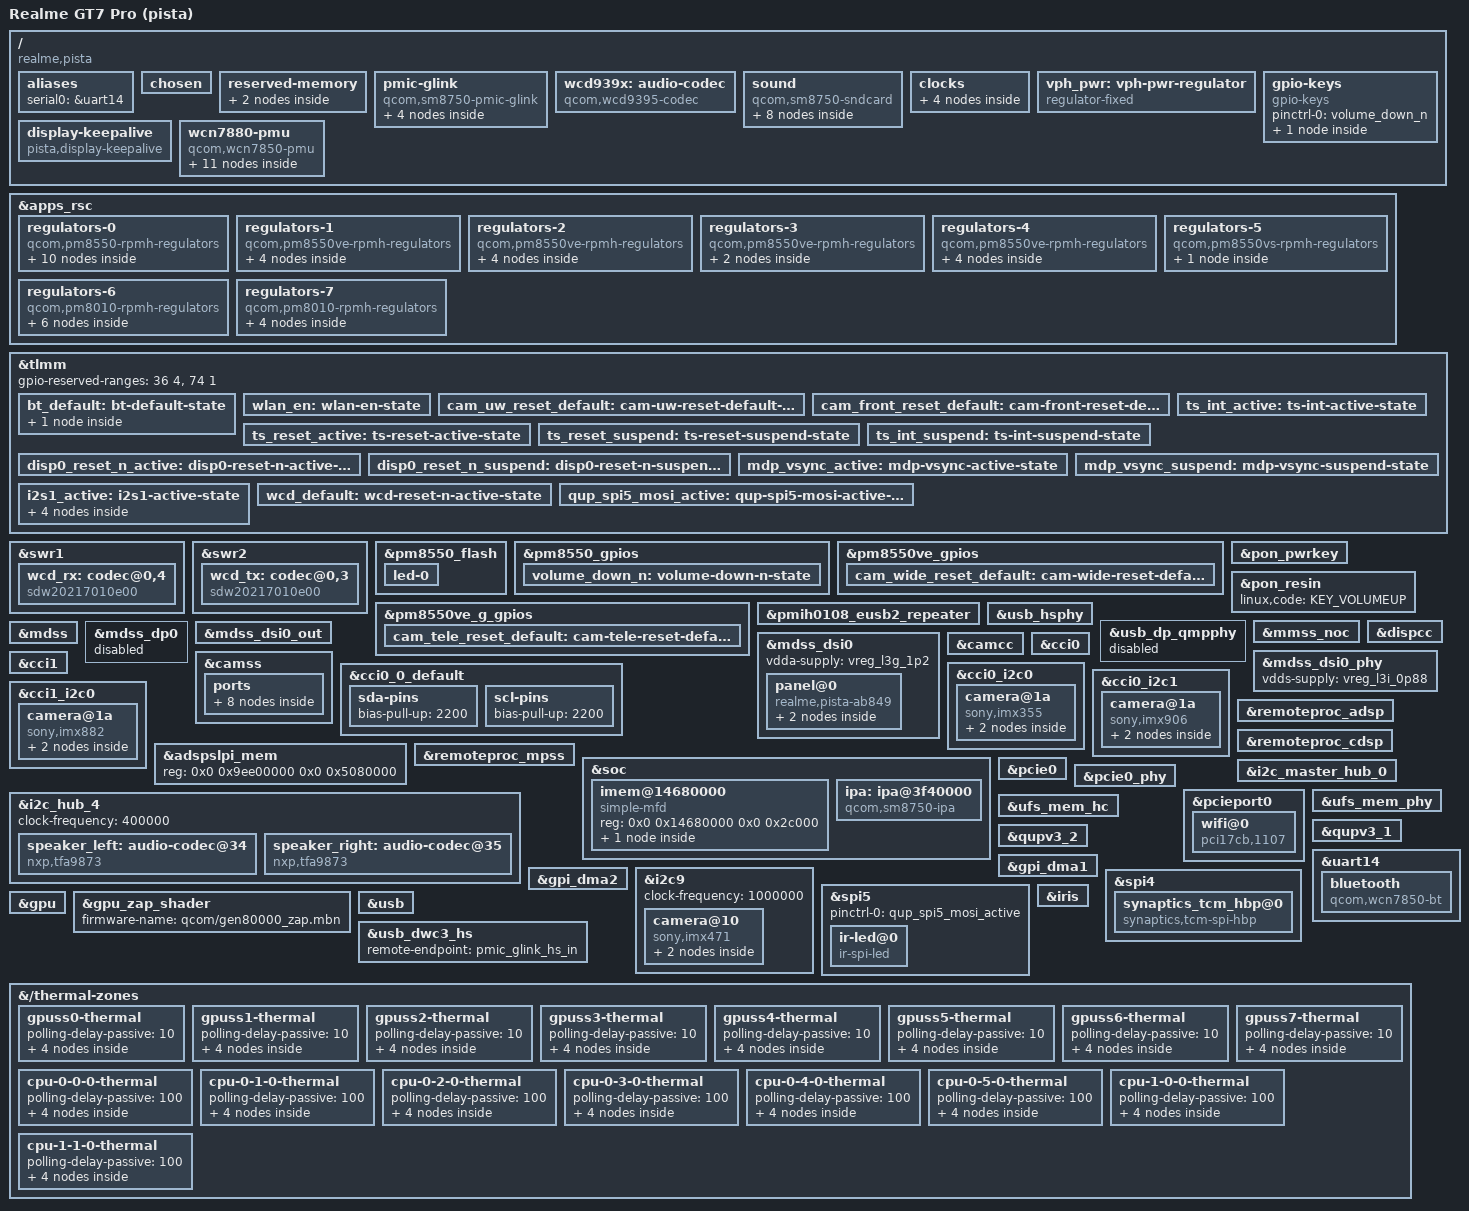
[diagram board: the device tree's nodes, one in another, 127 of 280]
// SPDX-License-Identifier: BSD-3-Clause
/*
 * Realme GT7 Pro (pista / RMX5010) mainline DT:
 * UEFI SimpleDRM + USB 2.0 Gadget + PCIe0 WCN7860 (peach) Wi-Fi 7 + UFS
 */

/dts-v1/;

#include <dt-bindings/firmware/qcom,scm.h>
#include <dt-bindings/gpio/gpio.h>
#include <dt-bindings/input/linux-event-codes.h>
#include <dt-bindings/leds/common.h>
#include <dt-bindings/regulator/qcom,rpmh-regulator.h>
#include <dt-bindings/thermal/thermal.h>
#include "sm8750.dtsi"
#include "pm8550.dtsi"
#define PMK8550VE_SID 8
#include "pm8550ve.dtsi"
#include "pmih0108.dtsi"
#include "pmk8550.dtsi"
#include "sm8750-pmics.dtsi"

/ {
	model = "Realme GT7 Pro (pista)";
	compatible = "realme,pista", "qcom,sm8750";
	chassis-type = "handset";

	aliases {
		serial0 = &uart14;
	};

	chosen {
		/* cmdline and EFI GOP framebuffer come from UEFI */
	};

	reserved-memory {
		rmtfs_mem: rmtfs@d7c00000 {
			compatible = "qcom,rmtfs-mem";
			reg = <0x0 0xd7c00000 0x0 0x400000>;
			no-map;

			qcom,client-id = <1>;
			qcom,vmid = <QCOM_SCM_VMID_MSS_MSA>;
		};
	};

	pmic-glink {
		compatible = "qcom,sm8750-pmic-glink",
			     "qcom,sm8550-pmic-glink",
			     "qcom,pmic-glink";
		#address-cells = <1>;
		#size-cells = <0>;

		connector@0 {
			compatible = "usb-c-connector";
			reg = <0>;

			power-role = "dual";
			data-role = "dual";

			ports {
				#address-cells = <1>;
				#size-cells = <0>;

				port@0 {
					reg = <0>;

					pmic_glink_hs_in: endpoint {
						remote-endpoint = <&usb_dwc3_hs>;
					};
				};
			};
		};
	};

	wcd939x: audio-codec {
		compatible = "qcom,wcd9395-codec", "qcom,wcd9390-codec";

		pinctrl-0 = <&wcd_default>;
		pinctrl-names = "default";

		qcom,micbias1-microvolt = <2700000>;
		qcom,micbias2-microvolt = <2700000>;
		qcom,micbias3-microvolt = <2700000>;
		qcom,micbias4-microvolt = <2700000>;
		qcom,mbhc-buttons-vthreshold-microvolt = <75000 150000 237000 500000 500000 500000 500000 500000>;
		qcom,mbhc-headset-vthreshold-microvolt = <1700000>;
		qcom,mbhc-headphone-vthreshold-microvolt = <50000>;
		qcom,rx-device = <&wcd_rx>;
		qcom,tx-device = <&wcd_tx>;

		reset-gpios = <&tlmm 101 GPIO_ACTIVE_LOW>;

		vdd-buck-supply = <&vreg_l15b_1p8>;
		vdd-rxtx-supply = <&vreg_l15b_1p8>;
		vdd-io-supply = <&vreg_l15b_1p8>;
		vdd-mic-bias-supply = <&vreg_bob1>;
		vdd-px-supply = <&vreg_l2i_1p2>;

		#sound-dai-cells = <1>;
	};

	sound {
		compatible = "qcom,sm8750-sndcard";
		model = "Realme-pista";

		pinctrl-0 = <&i2s1_active>;
		pinctrl-names = "default";

		audio-routing = "AMIC1", "MIC BIAS1",
				"AMIC2", "MIC BIAS2",
				"AMIC3", "MIC BIAS4",
				"AMIC4", "MIC BIAS3",
				"AMIC5", "MIC BIAS3",
				"TX SWR_INPUT0", "ADC1_OUTPUT",
				"TX SWR_INPUT1", "ADC2_OUTPUT",
				"TX SWR_INPUT2", "ADC3_OUTPUT",
				"TX SWR_INPUT3", "ADC4_OUTPUT";

		speaker-dai-link {
			link-name = "Speaker Playback";

			cpu {
				sound-dai = <&q6apmbedai SECONDARY_MI2S_RX>;
			};

			codec {
				sound-dai = <&speaker_left>, <&speaker_right>;
			};

			platform {
				sound-dai = <&q6apm>;
			};
		};

		wcd-capture-dai-link {
			link-name = "WCD Capture";

			codec {
				sound-dai = <&wcd939x 1>, <&swr2 0>, <&lpass_txmacro 0>;
			};

			cpu {
				sound-dai = <&q6apmbedai TX_CODEC_DMA_TX_3>;
			};

			platform {
				sound-dai = <&q6apm>;
			};
		};
	};

	reserved-memory {
		display_reserved: framebuffer@fc800000 {
			reg = <0x0 0xfc800000 0x0 0x2b00000>;
			no-map;
		};
	};

	clocks {
		xo_board: xo-board {
			compatible = "fixed-clock";
			clock-frequency = <76800000>;
			#clock-cells = <0>;
		};

		sleep_clk: sleep-clk {
			compatible = "fixed-clock";
			clock-frequency = <32000>;
			#clock-cells = <0>;
		};

		bi_tcxo_div2: bi-tcxo-div2-clk {
			compatible = "fixed-factor-clock";
			#clock-cells = <0>;
			clocks = <&rpmhcc RPMH_CXO_CLK>;
			clock-mult = <1>;
			clock-div = <2>;
		};

		bi_tcxo_ao_div2: bi-tcxo-ao-div2-clk {
			compatible = "fixed-factor-clock";
			#clock-cells = <0>;
			clocks = <&rpmhcc RPMH_CXO_CLK_A>;
			clock-mult = <1>;
			clock-div = <2>;
		};
	};

	vph_pwr: vph-pwr-regulator {
		compatible = "regulator-fixed";
		regulator-name = "vph_pwr";
		regulator-min-microvolt = <3700000>;
		regulator-max-microvolt = <3700000>;
		regulator-always-on;
		regulator-boot-on;
	};

	gpio-keys {
		compatible = "gpio-keys";

		pinctrl-0 = <&volume_down_n>;
		pinctrl-names = "default";

		key-volume-down {
			label = "Volume Down";
			linux,code = <KEY_VOLUMEDOWN>;
			gpios = <&pm8550_gpios 6 GPIO_ACTIVE_LOW>;
			debounce-interval = <15>;
			linux,can-disable;
			wakeup-source;
		};
	};

	/*
	 * Keep fw_devlink sync_state() pending on rpmhpd (MMCX), interconnects,
	 * and clocks so UEFI's active MDSS/OLED scanout is never powered down
	 * while running on simpledrm.
	 */
	display-keepalive {
		compatible = "pista,display-keepalive";
		power-domains = <&rpmhpd RPMHPD_MMCX>;
		interconnects = <&gem_noc MASTER_APPSS_PROC QCOM_ICC_TAG_ALWAYS
				 &mc_virt SLAVE_EBI1 QCOM_ICC_TAG_ALWAYS>,
				<&gem_noc MASTER_APPSS_PROC QCOM_ICC_TAG_ACTIVE_ONLY
				 &config_noc SLAVE_DISPLAY_CFG QCOM_ICC_TAG_ACTIVE_ONLY>;
		clocks = <&gcc GCC_DISP_HF_AXI_CLK>,
			 <&rpmhcc RPMH_CXO_CLK>;
		status = "okay";
	};

	/* Qualcomm FastConnect 7900 / WCN7860 (peach, PCI 17cb:110e) PMU */
	wcn7880-pmu {
		compatible = "qcom,wcn7850-pmu";

		pinctrl-names = "default";
		pinctrl-0 = <&wlan_en>, <&bt_default>;

		wlan-enable-gpios = <&tlmm 16 GPIO_ACTIVE_HIGH>;
		bt-enable-gpios = <&pm8550ve_f_gpios 3 GPIO_ACTIVE_HIGH>;

		vdd-supply = <&vreg_s5f_0p85>;
		vddio-supply = <&vreg_l3f_1p8>;
		vddio1p2-supply = <&vreg_l2f_1p2>;
		vddaon-supply = <&vreg_s4d_0p85>;
		vdddig-supply = <&vreg_s1d_0p97>;
		vddrfa1p2-supply = <&vreg_s7i_1p2>;
		vddrfa1p8-supply = <&vreg_s3g_1p8>;

		clocks = <&rpmhcc RPMH_RF_CLK1>;

		status = "okay";

		regulators {
			vreg_pmu_rfa_cmn: ldo0 {
				regulator-name = "vreg_pmu_rfa_cmn";
			};

			vreg_pmu_aon_0p59: ldo1 {
				regulator-name = "vreg_pmu_aon_0p59";
			};

			vreg_pmu_wlcx_0p8: ldo2 {
				regulator-name = "vreg_pmu_wlcx_0p8";
			};

			vreg_pmu_wlmx_0p85: ldo3 {
				regulator-name = "vreg_pmu_wlmx_0p85";
			};

			vreg_pmu_btcmx_0p85: ldo4 {
				regulator-name = "vreg_pmu_btcmx_0p85";
			};

			vreg_pmu_rfa_0p8: ldo5 {
				regulator-name = "vreg_pmu_rfa_0p8";
			};

			vreg_pmu_rfa_1p2: ldo6 {
				regulator-name = "vreg_pmu_rfa_1p2";
			};

			vreg_pmu_rfa_1p8: ldo7 {
				regulator-name = "vreg_pmu_rfa_1p8";
			};

			vreg_pmu_pcie_0p9: ldo8 {
				regulator-name = "vreg_pmu_pcie_0p9";
			};

			vreg_pmu_pcie_1p8: ldo9 {
				regulator-name = "vreg_pmu_pcie_1p8";
			};
		};
	};
};

&apps_rsc {
	regulators-0 {
		compatible = "qcom,pm8550-rpmh-regulators";

		vdd-bob1-supply = <&vph_pwr>;
		vdd-bob2-supply = <&vph_pwr>;
		vdd-l1-l4-l10-supply = <&vreg_s3g_1p8>;
		vdd-l2-l13-l14-supply = <&vreg_bob1>;
		vdd-l5-l16-supply = <&vreg_bob1>;
		vdd-l8-l9-supply = <&vreg_bob1>;
		vdd-l11-supply = <&vreg_s7i_1p2>;
		vdd-l12-supply = <&vreg_s3g_1p8>;
		vdd-l15-supply = <&vreg_s3g_1p8>;
		vdd-l17-supply = <&vreg_bob2>;

		qcom,pmic-id = "b";

		vreg_bob1: bob1 {
			regulator-name = "vreg_bob1";
			regulator-min-microvolt = <3008000>;
			regulator-max-microvolt = <4000000>;
			regulator-initial-mode = <RPMH_REGULATOR_MODE_HPM>;
		};

		vreg_bob2: bob2 {
			regulator-name = "vreg_bob2";
			regulator-min-microvolt = <2704000>;
			regulator-max-microvolt = <3008000>;
			regulator-initial-mode = <RPMH_REGULATOR_MODE_HPM>;
		};

		vreg_l4b_1p8: ldo4 {
			regulator-name = "vreg_l4b_1p8";
			regulator-min-microvolt = <1800000>;
			regulator-max-microvolt = <1800000>;
			regulator-initial-mode = <RPMH_REGULATOR_MODE_HPM>;
			regulator-allow-set-load;
			regulator-allowed-modes = <RPMH_REGULATOR_MODE_LPM
						   RPMH_REGULATOR_MODE_HPM>;
		};

		vreg_l5b_3p1: ldo5 {
			regulator-name = "vreg_l5b_3p1";
			regulator-min-microvolt = <3100000>;
			regulator-max-microvolt = <3148000>;
			regulator-initial-mode = <RPMH_REGULATOR_MODE_HPM>;
			regulator-allow-set-load;
			regulator-allowed-modes = <RPMH_REGULATOR_MODE_LPM
						   RPMH_REGULATOR_MODE_HPM>;
		};

		vreg_l9b_2p5: ldo9 {
			regulator-name = "vreg_l9b_2p5";
			regulator-min-microvolt = <2504000>;
			regulator-max-microvolt = <2504000>;
			regulator-initial-mode = <RPMH_REGULATOR_MODE_HPM>;
			regulator-allow-set-load;
			regulator-allowed-modes = <RPMH_REGULATOR_MODE_LPM
						   RPMH_REGULATOR_MODE_HPM>;
		};

		vreg_l11b_1p0: ldo11 {
			regulator-name = "vreg_l11b_1p0";
			regulator-min-microvolt = <1000000>;
			regulator-max-microvolt = <1100000>;
			regulator-initial-mode = <RPMH_REGULATOR_MODE_HPM>;
			regulator-allow-set-load;
			regulator-allowed-modes = <RPMH_REGULATOR_MODE_LPM
						   RPMH_REGULATOR_MODE_HPM>;
		};

		vreg_l12b_1p8: ldo12 {
			regulator-name = "vreg_l12b_1p8";
			regulator-min-microvolt = <1800000>;
			regulator-max-microvolt = <1800000>;
			regulator-initial-mode = <RPMH_REGULATOR_MODE_HPM>;
			regulator-allow-set-load;
			regulator-allowed-modes = <RPMH_REGULATOR_MODE_LPM
						   RPMH_REGULATOR_MODE_HPM>;
		};

		vreg_l13b_3p0: ldo13 {
			regulator-name = "vreg_l13b_3p0";
			regulator-min-microvolt = <3000000>;
			regulator-max-microvolt = <3000000>;
			regulator-initial-mode = <RPMH_REGULATOR_MODE_HPM>;
			regulator-allow-set-load;
			regulator-allowed-modes = <RPMH_REGULATOR_MODE_LPM
						   RPMH_REGULATOR_MODE_HPM>;
		};

		vreg_l15b_1p8: ldo15 {
			regulator-name = "vreg_l15b_1p8";
			regulator-min-microvolt = <1800000>;
			regulator-max-microvolt = <1800000>;
			regulator-initial-mode = <RPMH_REGULATOR_MODE_HPM>;
			regulator-allow-set-load;
			regulator-allowed-modes = <RPMH_REGULATOR_MODE_LPM
						   RPMH_REGULATOR_MODE_HPM>;
		};

		vreg_l17b_2p5: ldo17 {
			regulator-name = "vreg_l17b_2p5";
			regulator-min-microvolt = <2504000>;
			regulator-max-microvolt = <2504000>;
			regulator-initial-mode = <RPMH_REGULATOR_MODE_HPM>;
			regulator-allow-set-load;
			regulator-allowed-modes = <RPMH_REGULATOR_MODE_LPM
						   RPMH_REGULATOR_MODE_HPM>;
		};
	};

	regulators-1 {
		compatible = "qcom,pm8550ve-rpmh-regulators";

		vdd-l1-supply = <&vreg_s7i_1p2>;
		vdd-l2-supply = <&vreg_s1d_0p97>;
		vdd-s1-supply = <&vph_pwr>;
		vdd-s4-supply = <&vph_pwr>;

		qcom,pmic-id = "d";

		vreg_s1d_0p97: smps1 {
			regulator-name = "vreg_s1d_0p97";
			regulator-min-microvolt = <976000>;
			regulator-max-microvolt = <1100000>;
			regulator-initial-mode = <RPMH_REGULATOR_MODE_HPM>;
		};

		vreg_s4d_0p85: smps4 {
			regulator-name = "vreg_s4d_0p85";
			regulator-min-microvolt = <876000>;
			regulator-max-microvolt = <1036000>;
			regulator-initial-mode = <RPMH_REGULATOR_MODE_HPM>;
		};

		vreg_l1d_1p2: ldo1 {
			regulator-name = "vreg_l1d_1p2";
			regulator-min-microvolt = <1200000>;
			regulator-max-microvolt = <1200000>;
			regulator-initial-mode = <RPMH_REGULATOR_MODE_HPM>;
			regulator-allow-set-load;
			regulator-allowed-modes = <RPMH_REGULATOR_MODE_LPM
						   RPMH_REGULATOR_MODE_HPM>;
		};

		vreg_l2d_0p88: ldo2 {
			regulator-name = "vreg_l2d_0p88";
			regulator-min-microvolt = <880000>;
			regulator-max-microvolt = <912000>;
			regulator-initial-mode = <RPMH_REGULATOR_MODE_HPM>;
			regulator-allow-set-load;
			regulator-allowed-modes = <RPMH_REGULATOR_MODE_LPM
						   RPMH_REGULATOR_MODE_HPM>;
		};
	};

	regulators-2 {
		compatible = "qcom,pm8550ve-rpmh-regulators";

		vdd-l1-supply = <&vreg_s1d_0p97>;
		vdd-l2-supply = <&vreg_s7i_1p2>;
		vdd-l3-supply = <&vreg_s3g_1p8>;
		vdd-s5-supply = <&vph_pwr>;

		qcom,pmic-id = "f";

		vreg_s5f_0p85: smps5 {
			regulator-name = "vreg_s5f_0p85";
			regulator-min-microvolt = <876000>;
			regulator-max-microvolt = <1000000>;
			regulator-initial-mode = <RPMH_REGULATOR_MODE_HPM>;
		};

		vreg_l1f_0p88: ldo1 {
			regulator-name = "vreg_l1f_0p88";
			regulator-min-microvolt = <880000>;
			regulator-max-microvolt = <920000>;
			regulator-initial-mode = <RPMH_REGULATOR_MODE_HPM>;
		};

		vreg_l2f_1p2: ldo2 {
			regulator-name = "vreg_l2f_1p2";
			regulator-min-microvolt = <1200000>;
			regulator-max-microvolt = <1200000>;
			regulator-initial-mode = <RPMH_REGULATOR_MODE_HPM>;
			regulator-allow-set-load;
			regulator-allowed-modes = <RPMH_REGULATOR_MODE_LPM
						   RPMH_REGULATOR_MODE_HPM>;
		};

		vreg_l3f_1p8: ldo3 {
			regulator-name = "vreg_l3f_1p8";
			regulator-min-microvolt = <1800000>;
			regulator-max-microvolt = <1800000>;
			regulator-initial-mode = <RPMH_REGULATOR_MODE_HPM>;
			regulator-allow-set-load;
			regulator-allowed-modes = <RPMH_REGULATOR_MODE_LPM
						   RPMH_REGULATOR_MODE_HPM>;
		};
	};

	regulators-3 {
		compatible = "qcom,pm8550ve-rpmh-regulators";

		vdd-l3-supply = <&vreg_s7i_1p2>;
		vdd-s3-supply = <&vph_pwr>;

		qcom,pmic-id = "g";

		vreg_s3g_1p8: smps3 {
			regulator-name = "vreg_s3g_1p8";
			regulator-min-microvolt = <1864000>;
			regulator-max-microvolt = <2000000>;
			regulator-initial-mode = <RPMH_REGULATOR_MODE_HPM>;
		};

		vreg_l3g_1p2: ldo3 {
			regulator-name = "vreg_l3g_1p2";
			regulator-min-microvolt = <1200000>;
			regulator-max-microvolt = <1256000>;
			regulator-initial-mode = <RPMH_REGULATOR_MODE_HPM>;
			regulator-allow-set-load;
			regulator-allowed-modes = <RPMH_REGULATOR_MODE_LPM
						   RPMH_REGULATOR_MODE_HPM>;
		};
	};

	regulators-4 {
		compatible = "qcom,pm8550ve-rpmh-regulators";

		vdd-l1-supply = <&vreg_s7i_1p2>;
		vdd-l2-supply = <&vreg_s7i_1p2>;
		vdd-l3-supply = <&vreg_s1d_0p97>;
		vdd-s7-supply = <&vph_pwr>;

		qcom,pmic-id = "i";

		vreg_s7i_1p2: smps7 {
			regulator-name = "vreg_s7i_1p2";
			regulator-min-microvolt = <1312000>;
			regulator-max-microvolt = <1340000>;
			regulator-initial-mode = <RPMH_REGULATOR_MODE_HPM>;
		};

		vreg_l1i_1p2: ldo1 {
			regulator-name = "vreg_l1i_1p2";
			regulator-min-microvolt = <1200000>;
			regulator-max-microvolt = <1200000>;
			regulator-initial-mode = <RPMH_REGULATOR_MODE_HPM>;
			regulator-allow-set-load;
			regulator-allowed-modes = <RPMH_REGULATOR_MODE_LPM
						   RPMH_REGULATOR_MODE_HPM>;
		};

		vreg_l2i_1p2: ldo2 {
			regulator-name = "vreg_l2i_1p2";
			regulator-min-microvolt = <1200000>;
			regulator-max-microvolt = <1200000>;
			regulator-initial-mode = <RPMH_REGULATOR_MODE_HPM>;
			regulator-allow-set-load;
			regulator-allowed-modes = <RPMH_REGULATOR_MODE_LPM
						   RPMH_REGULATOR_MODE_HPM>;
		};

		vreg_l3i_0p88: ldo3 {
			regulator-name = "vreg_l3i_0p88";
			regulator-min-microvolt = <880000>;
			regulator-max-microvolt = <912000>;
			regulator-initial-mode = <RPMH_REGULATOR_MODE_HPM>;
			regulator-allow-set-load;
			regulator-allowed-modes = <RPMH_REGULATOR_MODE_LPM
						   RPMH_REGULATOR_MODE_HPM>;
		};
	};

	regulators-5 {
		compatible = "qcom,pm8550vs-rpmh-regulators";

		vdd-l1-supply = <&vreg_s1d_0p97>;

		qcom,pmic-id = "j";

		vreg_l1j_0p91: ldo1 {
			regulator-name = "vreg_l1j_0p91";
			regulator-min-microvolt = <880000>;
			regulator-max-microvolt = <920000>;
			regulator-initial-mode = <RPMH_REGULATOR_MODE_HPM>;
			regulator-allow-set-load;
			regulator-allowed-modes = <RPMH_REGULATOR_MODE_LPM
						   RPMH_REGULATOR_MODE_HPM>;
		};
	};

	regulators-6 {
		compatible = "qcom,pm8010-rpmh-regulators";
		qcom,pmic-id = "m";

		vdd-l1-l2-supply = <&vreg_s7i_1p2>;
		vdd-l3-l4-supply = <&vreg_bob1>;
		vdd-l5-supply = <&vreg_s3g_1p8>;
		vdd-l6-supply = <&vreg_s3g_1p8>;
		vdd-l7-supply = <&vreg_bob1>;

		vreg_l1m_1p056: ldo1 {
			regulator-name = "vreg_l1m_1p056";
			regulator-min-microvolt = <1056000>;
			regulator-max-microvolt = <1056000>;
			regulator-initial-mode = <RPMH_REGULATOR_MODE_HPM>;
			regulator-allow-set-load;
			regulator-allowed-modes = <RPMH_REGULATOR_MODE_LPM
						   RPMH_REGULATOR_MODE_HPM>;
		};

		vreg_l2m_1p12: ldo2 {
			regulator-name = "vreg_l2m_1p12";
			regulator-min-microvolt = <1120000>;
			regulator-max-microvolt = <1120000>;
			regulator-initial-mode = <RPMH_REGULATOR_MODE_HPM>;
			regulator-allow-set-load;
			regulator-allowed-modes = <RPMH_REGULATOR_MODE_LPM
						   RPMH_REGULATOR_MODE_HPM>;
		};

		vreg_l3m_2p8: ldo3 {
			regulator-name = "vreg_l3m_2p8";
			regulator-min-microvolt = <2800000>;
			regulator-max-microvolt = <2800000>;
			regulator-initial-mode = <RPMH_REGULATOR_MODE_HPM>;
		};

		vreg_l4m_2p8: ldo4 {
			regulator-name = "vreg_l4m_2p8";
			regulator-min-microvolt = <2800000>;
			regulator-max-microvolt = <2800000>;
			regulator-initial-mode = <RPMH_REGULATOR_MODE_HPM>;
		};

		vreg_l5m_1p8: ldo5 {
			regulator-name = "vreg_l5m_1p8";
			regulator-min-microvolt = <1800000>;
			regulator-max-microvolt = <1800000>;
			regulator-initial-mode = <RPMH_REGULATOR_MODE_HPM>;
		};

		vreg_l6m_1p8: ldo6 {
			regulator-name = "vreg_l6m_1p8";
			regulator-min-microvolt = <1800000>;
			regulator-max-microvolt = <1800000>;
			regulator-initial-mode = <RPMH_REGULATOR_MODE_HPM>;
		};
	};

	regulators-7 {
		compatible = "qcom,pm8010-rpmh-regulators";
		qcom,pmic-id = "n";

		/* On pista, PM8010N VIN_L1_L2 is fed by smpd1 (max 1100 mV in AOP VRM) */
		vdd-l1-l2-supply = <&vreg_s1d_0p97>;
		vdd-l3-l4-supply = <&vreg_bob1>;
		vdd-l5-supply = <&vreg_bob2>;
		vdd-l6-supply = <&vreg_bob2>;
		vdd-l7-supply = <&vreg_bob1>;

		vreg_l1n_1p1: ldo1 {
			regulator-name = "vreg_l1n_1p1";
			regulator-min-microvolt = <1096000>;
			regulator-max-microvolt = <1096000>;
			regulator-initial-mode = <RPMH_REGULATOR_MODE_HPM>;
		};

		vreg_l3n_2p8: ldo3 {
			regulator-name = "vreg_l3n_2p8";
			regulator-min-microvolt = <2800000>;
			regulator-max-microvolt = <2800000>;
			regulator-initial-mode = <RPMH_REGULATOR_MODE_HPM>;
		};

		vreg_l4n_2p7: ldo4 {
			regulator-name = "vreg_l4n_2p7";
			regulator-min-microvolt = <2704000>;
			regulator-max-microvolt = <2704000>;
			regulator-initial-mode = <RPMH_REGULATOR_MODE_HPM>;
		};

		vreg_l7n_3p1: ldo7 {
			regulator-name = "vreg_l7n_3p1";
			regulator-min-microvolt = <3104000>;
			regulator-max-microvolt = <3104000>;
			regulator-initial-mode = <RPMH_REGULATOR_MODE_HPM>;
		};
	};
};

&tlmm {
	gpio-reserved-ranges = <36 4>, <74 1>;

	bt_default: bt-default-state {
		sw-ctrl-pins {
			pins = "gpio18";
			function = "gpio";
			bias-pull-down;
		};
	};

	wlan_en: wlan-en-state {
		pins = "gpio16";
		function = "gpio";
		drive-strength = <8>;
		bias-pull-down;
	};

	cam_uw_reset_default: cam-uw-reset-default-state {
		pins = "gpio178";
		function = "gpio";
		drive-strength = <2>;
		bias-disable;
	};

	cam_front_reset_default: cam-front-reset-default-state {
		pins = "gpio7";
		function = "gpio";
		drive-strength = <2>;
		bias-disable;
	};

	ts_reset_active: ts-reset-active-state {
		pins = "gpio161";
		function = "gpio";
		bias-disable;
		output-low;
		drive-strength = <8>;
	};

	ts_int_active: ts-int-active-state {
		pins = "gpio162";
		function = "gpio";
		bias-pull-up;
		drive-strength = <8>;
		input-enable;
	};

	ts_reset_suspend: ts-reset-suspend-state {
		pins = "gpio161";
		function = "gpio";
		bias-pull-down;
		drive-strength = <2>;
	};

	ts_int_suspend: ts-int-suspend-state {
		pins = "gpio162";
		function = "gpio";
		bias-pull-down;
		drive-strength = <2>;
	};

	disp0_reset_n_active: disp0-reset-n-active-state {
		pins = "gpio98";
		function = "gpio";
		drive-strength = <8>;
		bias-disable;
	};

	disp0_reset_n_suspend: disp0-reset-n-suspend-state {
		pins = "gpio98";
		function = "gpio";
		drive-strength = <2>;
		bias-pull-down;
	};

	mdp_vsync_active: mdp-vsync-active-state {
		pins = "gpio86";
		function = "mdp_vsync";
		drive-strength = <2>;
		bias-pull-down;
	};

	mdp_vsync_suspend: mdp-vsync-suspend-state {
		pins = "gpio86";
		function = "mdp_vsync";
		drive-strength = <2>;
		bias-pull-down;
	};

	/* Secondary MI2S to dual NXP TFA9874 speaker amplifiers */
	i2s1_active: i2s1-active-state {
		sck-pins {
			pins = "gpio121";
			function = "i2s1_sck";
			drive-strength = <4>;
			bias-disable;
		};

		data0-pins {
			pins = "gpio122";
			function = "i2s1_data0";
			drive-strength = <4>;
			bias-disable;
		};

		ws-pins {
			pins = "gpio123";
			function = "i2s1_ws";
			drive-strength = <4>;
			bias-disable;
		};

		data1-pins {
			pins = "gpio124";
			function = "i2s1_data1";
			drive-strength = <4>;
			bias-disable;
		};
	};

	wcd_default: wcd-reset-n-active-state {
		pins = "gpio101";
		function = "gpio";
		drive-strength = <16>;
		bias-disable;
		output-low;
	};

	qup_spi5_mosi_active: qup-spi5-mosi-active-state {
		pins = "gpio53";
		function = "qup1_se5";
		drive-strength = <6>;
		bias-disable;
	};
};

&swr1 {
	status = "okay";

	/* WCD9395 RX */
	wcd_rx: codec@0,4 {
		compatible = "sdw20217010e00";
		reg = <0 4>;
		qcom,rx-port-mapping = <1 2 3 4 5 9>;
	};
};

&swr2 {
	status = "okay";

	/* WCD9395 TX */
	wcd_tx: codec@0,3 {
		compatible = "sdw20217010e00";
		reg = <0 3>;
		qcom,tx-port-mapping = <2 2 3 4>;
	};
};

&pm8550_flash {
	status = "okay";

	led-0 {
		function = LED_FUNCTION_FLASH;
		color = <LED_COLOR_ID_WHITE>;
		led-sources = <1>;
		led-max-microamp = <500000>;
		flash-max-microamp = <1500000>;
		flash-max-timeout-us = <1280000>;
	};
};

&pm8550_gpios {
	volume_down_n: volume-down-n-state {
		pins = "gpio6";
		function = "normal";
		bias-pull-up;
		input-enable;
		power-source = <1>;
	};
};

&pm8550ve_gpios {
	cam_wide_reset_default: cam-wide-reset-default-state {
		pins = "gpio5";
		function = "normal";
		input-disable;
		output-enable;
		bias-disable;
		output-low;
		power-source = <1>;
	};
};

&pm8550ve_g_gpios {
	cam_tele_reset_default: cam-tele-reset-default-state {
		pins = "gpio5";
		function = "normal";
		input-disable;
		output-enable;
		bias-disable;
		output-low;
		power-source = <1>;
	};
};

&pon_pwrkey {
	status = "okay";
};

&pon_resin {
	linux,code = <KEY_VOLUMEUP>;
	status = "okay";
};

&pmih0108_eusb2_repeater {
	vdd18-supply = <&vreg_l15b_1p8>;
	vdd3-supply = <&vreg_l5b_3p1>;
	status = "okay";
};

&usb_hsphy {
	vdd-supply = <&vreg_l2d_0p88>;
	vdda12-supply = <&vreg_l3g_1p2>;
	phys = <&pmih0108_eusb2_repeater>;
	status = "okay";
};

&usb_dp_qmpphy {
	status = "disabled";
};

&mmss_noc {
	status = "okay";
};

&dispcc {
	status = "okay";
};

&mdss {
	status = "okay";
};

&mdss_dp0 {
	status = "disabled";
};

&mdss_dsi0 {
	vdda-supply = <&vreg_l3g_1p2>;
	status = "okay";

	panel@0 {
		compatible = "realme,pista-ab849";
		reg = <0>;

		pinctrl-names = "default", "sleep";
		pinctrl-0 = <&disp0_reset_n_active>, <&mdp_vsync_active>;
		pinctrl-1 = <&disp0_reset_n_suspend>, <&mdp_vsync_suspend>;

		vddio-supply = <&vreg_l12b_1p8>;
		vci-supply = <&vreg_l13b_3p0>;
		vdd-supply = <&vreg_l11b_1p0>;

		enable-gpios = <&pm8550ve_f_gpios 7 GPIO_ACTIVE_HIGH>;
		reset-gpios = <&tlmm 98 GPIO_ACTIVE_LOW>;

		port {
			panel0_in: endpoint {
				remote-endpoint = <&mdss_dsi0_out>;
			};
		};
	};
};

&mdss_dsi0_out {
	remote-endpoint = <&panel0_in>;
	data-lanes = <0 1 2 3>;
};

&mdss_dsi0_phy {
	vdds-supply = <&vreg_l3i_0p88>;
	status = "okay";
};

&camcc {
	status = "okay";
};

&camss {
	vdd-csiphy0-0p9-supply = <&vreg_l1f_0p88>;
	vdd-csiphy0-1p2-supply = <&vreg_l3g_1p2>;
	vdd-csiphy1-0p9-supply = <&vreg_l1f_0p88>;
	vdd-csiphy1-1p2-supply = <&vreg_l3g_1p2>;
	vdd-csiphy2-0p9-supply = <&vreg_l3i_0p88>;
	vdd-csiphy2-1p2-supply = <&vreg_l3g_1p2>;
	vdd-csiphy3-0p9-supply = <&vreg_l1f_0p88>;
	vdd-csiphy3-1p2-supply = <&vreg_l3g_1p2>;
	vdd-csiphy4-0p9-supply = <&vreg_l3i_0p88>;
	vdd-csiphy4-1p2-supply = <&vreg_l3g_1p2>;
	vdd-csiphy5-0p9-supply = <&vreg_l1f_0p88>;
	vdd-csiphy5-1p2-supply = <&vreg_l3g_1p2>;

	status = "okay";

	ports {
		port@1 {
			reg = <1>;

			camss_csiphy1_ep: endpoint {
				bus-type = <1>; /* MIPI CSI-2 C-PHY */
				data-lanes = <0 1 2>;
				remote-endpoint = <&imx882_ep>;
			};
		};

		port@2 {
			reg = <2>;

			camss_csiphy2_ep: endpoint {
				bus-type = <1>; /* MIPI CSI-2 C-PHY */
				data-lanes = <0 1 2>;
				remote-endpoint = <&imx906_ep>;
			};
		};

		port@3 {
			reg = <3>;

			camss_csiphy3_ep: endpoint {
				data-lanes = <0 1 2 3>;
				remote-endpoint = <&imx355_ep>;
			};
		};

		port@4 {
			reg = <4>;

			camss_csiphy4_ep: endpoint {
				data-lanes = <0 1 2 3>;
				remote-endpoint = <&imx471_ep>;
			};
		};
	};
};

&cci0_0_default {
	sda-pins {
		bias-pull-up = <2200>;
	};

	scl-pins {
		bias-pull-up = <2200>;
	};
};

&cci0 {
	assigned-clocks = <&camcc CAM_CC_CCI_0_CLK>;
	assigned-clock-rates = <37500000>;
	status = "okay";
};

&cci0_i2c0 {
	/* Rear 8MP Ultrawide (Sony IMX355) -> CSIPHY3 */
	camera@1a {
		compatible = "sony,imx355";
		reg = <0x1a>;

		reset-gpios = <&tlmm 178 GPIO_ACTIVE_LOW>;
		pinctrl-names = "default";
		pinctrl-0 = <&cam2_default &cam_uw_reset_default>;

		clocks = <&cambistmclkcc CAM_BIST_MCLK_CC_MCLK2_CLK>;
		assigned-clocks = <&cambistmclkcc CAM_BIST_MCLK_CC_MCLK2_CLK>;
		assigned-clock-rates = <19200000>;

		avdd-supply = <&vreg_l4n_2p7>;
		dvdd-supply = <&vreg_l1i_1p2>;
		dovdd-supply = <&vreg_l5m_1p8>;

		orientation = <1>;
		rotation = <270>;

		port {
			imx355_ep: endpoint {
				data-lanes = <1 2 3 4>;
				link-frequencies = /bits/ 64 <360000000>;
				remote-endpoint = <&camss_csiphy3_ep>;
			};
		};
	};
};

&cci0_i2c1 {
	/* Rear 50MP Main Wide (Sony IMX906) -> CSIPHY2 (C-PHY 3-trio) */
	camera@1a {
		compatible = "sony,imx906";
		reg = <0x1a>;

		reset-gpios = <&pm8550ve_gpios 5 GPIO_ACTIVE_LOW>;
		pinctrl-names = "default";
		pinctrl-0 = <&cam1_default &cam_wide_reset_default>;

		clocks = <&cambistmclkcc CAM_BIST_MCLK_CC_MCLK1_CLK>;
		assigned-clocks = <&cambistmclkcc CAM_BIST_MCLK_CC_MCLK1_CLK>;
		assigned-clock-rates = <19200000>;

		vana-supply = <&vreg_l4m_2p8>;
		vdig-supply = <&vreg_l2m_1p12>;
		vio-supply = <&vreg_l5m_1p8>;
		vcustom1-supply = <&vreg_l6m_1p8>;

		orientation = <1>;
		rotation = <270>;

		port {
			imx906_ep: endpoint {
				bus-type = <1>; /* MIPI CSI-2 C-PHY */
				data-lanes = <0 1 2>;
				link-frequencies = /bits/ 64 <1634400000>;
				remote-endpoint = <&camss_csiphy2_ep>;
			};
		};
	};
};

&cci1 {
	/* Only bind cci1_0 (gpio117/118); gpio164 on cci1_1 is speaker_right reset */
	pinctrl-0 = <&cci1_0_default>;
	pinctrl-1 = <&cci1_0_sleep>;
	assigned-clocks = <&camcc CAM_CC_CCI_1_CLK>;
	assigned-clock-rates = <37500000>;
	status = "okay";
};

&cci1_i2c0 {
	/* Rear 50MP 3x Periscope Telephoto (Sony IMX882 / LYT-600) -> CSIPHY1 (C-PHY 3-trio) */
	camera@1a {
		compatible = "sony,imx882";
		reg = <0x1a>;

		reset-gpios = <&pm8550ve_g_gpios 5 GPIO_ACTIVE_LOW>;
		pinctrl-names = "default";
		pinctrl-0 = <&cam3_default &cam_tele_reset_default>;

		clocks = <&cambistmclkcc CAM_BIST_MCLK_CC_MCLK3_CLK>;
		assigned-clocks = <&cambistmclkcc CAM_BIST_MCLK_CC_MCLK3_CLK>;
		assigned-clock-rates = <19200000>;

		vana-supply = <&vreg_l3m_2p8>;
		vdig-supply = <&vreg_l1n_1p1>;
		vio-supply = <&vreg_l5m_1p8>;

		orientation = <1>;
		rotation = <270>;

		port {
			imx882_ep: endpoint {
				bus-type = <1>; /* MIPI CSI-2 C-PHY */
				data-lanes = <0 1 2>;
				link-frequencies = /bits/ 64 <1632000000>;
				remote-endpoint = <&camss_csiphy1_ep>;
			};
		};
	};
};

/* GT7 Pro stock ADSP image spans 80.5 MiB (0x5080000), larger than upstream 0x3a80000 */
&adspslpi_mem {
	reg = <0x0 0x9ee00000 0x0 0x5080000>;
};

&remoteproc_adsp {
	firmware-name = "qcom/sm8750/realme/pista/adsp.mbn",
			"qcom/sm8750/realme/pista/adsp_dtb.mbn";
	status = "okay";
};

&remoteproc_cdsp {
	firmware-name = "qcom/sm8750/realme/pista/cdsp.mbn",
			"qcom/sm8750/realme/pista/cdsp_dtb.mbn";
	status = "okay";
};

&remoteproc_mpss {
	firmware-name = "qcom/sm8750/realme/pista/modem.mbn",
			"qcom/sm8750/realme/pista/modem_dtb.mbn";
	status = "okay";
};

&soc {
	imem@14680000 {
		compatible = "simple-mfd";
		reg = <0x0 0x14680000 0x0 0x2c000>;
		#address-cells = <1>;
		#size-cells = <1>;
		ranges = <0x0 0x0 0x14680000 0x2c000>;

		ipa_modem_tables: modem-tables@3000 {
			reg = <0x3000 0x2000>;
		};
	};

	ipa: ipa@3f40000 {
		compatible = "qcom,sm8750-ipa";

		iommus = <&apps_smmu 0x4a0 0x0>,
			 <&apps_smmu 0x4a2 0x0>;
		reg = <0x0 0x03f40000 0x0 0x10000>,
		      <0x0 0x03f50000 0x0 0x5000>,
		      <0x0 0x03e04000 0x0 0xfc000>;
		reg-names = "ipa-reg",
			    "ipa-shared",
			    "gsi";

		interrupts-extended = <&intc GIC_SPI 655 IRQ_TYPE_LEVEL_HIGH>,
				      <&intc GIC_SPI 432 IRQ_TYPE_LEVEL_HIGH>,
				      <&ipa_smp2p_in 0 IRQ_TYPE_EDGE_RISING>,
				      <&ipa_smp2p_in 1 IRQ_TYPE_EDGE_RISING>;
		interrupt-names = "ipa",
				  "gsi",
				  "ipa-clock-query",
				  "ipa-setup-ready";

		clocks = <&rpmhcc RPMH_IPA_CLK>;
		clock-names = "core";

		interconnects = <&aggre2_noc MASTER_IPA QCOM_ICC_TAG_ALWAYS
				 &mc_virt SLAVE_EBI1 QCOM_ICC_TAG_ALWAYS>,
				<&gem_noc MASTER_APPSS_PROC QCOM_ICC_TAG_ACTIVE_ONLY
				 &cnoc_main SLAVE_IPA_CFG QCOM_ICC_TAG_ACTIVE_ONLY>;
		interconnect-names = "memory",
				     "config";

		qcom,qmp = <&aoss_qmp>;

		qcom,smem-states = <&ipa_smp2p_out 0>,
				   <&ipa_smp2p_out 1>;
		qcom,smem-state-names = "ipa-clock-enabled-valid",
					"ipa-clock-enabled";

		qcom,gsi-loader = "self";
		memory-region = <&ipa_gsi_mem>;
		firmware-name = "qcom/sm8750/realme/pista/ipa_fws.mbn";
		sram = <&ipa_modem_tables>;

		status = "okay";
	};
};

&i2c_master_hub_0 {
	status = "okay";
};

&i2c_hub_4 {
	clock-frequency = <400000>;
	status = "okay";

	speaker_left: audio-codec@34 {
		compatible = "nxp,tfa9873";
		reg = <0x34>;
		vdd-supply = <&vreg_l15b_1p8>;
		reset-gpios = <&tlmm 2 GPIO_ACTIVE_HIGH>;
		nxp,tdm-slot = <0>;
		#sound-dai-cells = <0>;
		sound-name-prefix = "Left";
	};

	speaker_right: audio-codec@35 {
		compatible = "nxp,tfa9873";
		reg = <0x35>;
		vdd-supply = <&vreg_l15b_1p8>;
		reset-gpios = <&tlmm 164 GPIO_ACTIVE_HIGH>;
		nxp,tdm-slot = <1>;
		#sound-dai-cells = <0>;
		sound-name-prefix = "Right";
	};
};

&pcie0 {
	wake-gpios = <&tlmm 104 GPIO_ACTIVE_HIGH>;
	perst-gpios = <&tlmm 102 GPIO_ACTIVE_LOW>;

	pinctrl-0 = <&pcie0_default_state>;
	pinctrl-names = "default";

	status = "okay";
};

&pcie0_phy {
	vdda-phy-supply = <&vreg_l1f_0p88>;
	vdda-pll-supply = <&vreg_l3g_1p2>;

	status = "okay";
};

&pcieport0 {
	wifi@0 {
		compatible = "pci17cb,1107";
		reg = <0x10000 0x0 0x0 0x0 0x0>;

		vddrfacmn-supply = <&vreg_pmu_rfa_cmn>;
		vddaon-supply = <&vreg_pmu_aon_0p59>;
		vddwlcx-supply = <&vreg_pmu_wlcx_0p8>;
		vddwlmx-supply = <&vreg_pmu_wlmx_0p85>;
		vddrfa0p8-supply = <&vreg_pmu_rfa_0p8>;
		vddrfa1p2-supply = <&vreg_pmu_rfa_1p2>;
		vddrfa1p8-supply = <&vreg_pmu_rfa_1p8>;
		vddpcie0p9-supply = <&vreg_pmu_pcie_0p9>;
		vddpcie1p8-supply = <&vreg_pmu_pcie_1p8>;
	};
};

&ufs_mem_phy {
	vdda-phy-supply = <&vreg_l1j_0p91>;
	vdda-pll-supply = <&vreg_l3g_1p2>;

	status = "okay";
};

&ufs_mem_hc {
	reset-gpios = <&tlmm 215 GPIO_ACTIVE_LOW>;

	vcc-supply = <&vreg_l17b_2p5>;
	vcc-max-microamp = <1300000>;
	vccq-supply = <&vreg_l1d_1p2>;
	vccq-max-microamp = <1200000>;

	status = "okay";
};

&qupv3_1 {
	status = "okay";
};

&qupv3_2 {
	status = "okay";
};

&uart14 {
	pinctrl-0 = <&qup_uart14_default>, <&qup_uart14_cts_rts>;
	status = "okay";

	bluetooth {
		compatible = "qcom,wcn7850-bt";

		vddrfacmn-supply = <&vreg_pmu_rfa_cmn>;
		vddaon-supply = <&vreg_pmu_aon_0p59>;
		vddwlcx-supply = <&vreg_pmu_wlcx_0p8>;
		vddwlmx-supply = <&vreg_pmu_wlmx_0p85>;
		vddrfa0p8-supply = <&vreg_pmu_rfa_0p8>;
		vddrfa1p2-supply = <&vreg_pmu_rfa_1p2>;
		vddrfa1p8-supply = <&vreg_pmu_rfa_1p8>;

		max-speed = <8000000>;
	};
};

&gpi_dma1 {
	status = "okay";
};

&gpi_dma2 {
	status = "okay";
};

&i2c9 {
	clock-frequency = <1000000>;
	status = "okay";

	/* Front 16MP Selfie (Sony IMX471 / IMX480) -> CSIPHY4 */
	camera@10 {
		compatible = "sony,imx471";
		reg = <0x10>;

		reset-gpios = <&tlmm 7 GPIO_ACTIVE_LOW>;
		pinctrl-names = "default";
		pinctrl-0 = <&cam4_default &cam_front_reset_default>;

		clocks = <&cambistmclkcc CAM_BIST_MCLK_CC_MCLK4_CLK>;
		assigned-clocks = <&cambistmclkcc CAM_BIST_MCLK_CC_MCLK4_CLK>;
		assigned-clock-rates = <19200000>;

		vana-supply = <&vreg_l3m_2p8>;
		vdig-supply = <&vreg_l1m_1p056>;
		vio-supply = <&vreg_l5m_1p8>;

		orientation = <0>;
		rotation = <90>;

		port {
			imx471_ep: endpoint {
				data-lanes = <1 2 3 4>;
				link-frequencies = /bits/ 64 <200000000>;
				remote-endpoint = <&camss_csiphy4_ep>;
			};
		};
	};
};

&spi4 {
	status = "okay";

	synaptics_tcm_hbp@0 {
		compatible = "synaptics,tcm-spi-hbp";
		reg = <0>;
		chip-name = "S3910";
		spi-max-frequency = <19000000>;
		interrupt-parent = <&tlmm>;
		interrupts = <162 0x2008>;
		vdd-supply = <&vreg_l4b_1p8>;
		synaptics,irq-gpio = <&tlmm 162 0x2008>;
		synaptics,reset-gpio = <&tlmm 161 GPIO_ACTIVE_LOW>;
		synaptics,avdd-gpio = <&pm8550vs_j_gpios 3 GPIO_ACTIVE_LOW>;
		pinctrl-names = "ts_spi_active", "ts_spi_suspend";
		pinctrl-0 = <&ts_int_active &ts_reset_active>;
		pinctrl-1 = <&ts_int_suspend &ts_reset_suspend>;
		panel_type = <3 8>;
		firmware_name = "AB849";
		touchpanel,panel-coords = <20224 44480>;
		touchpanel,tx-rx-num = <17 38>;
		touchpanel,tp_ic_type = <2>;
	};
};

&spi5 {
	pinctrl-0 = <&qup_spi5_mosi_active>;
	pinctrl-names = "default";
	status = "okay";

	ir-led@0 {
		compatible = "ir-spi-led";
		reg = <0>;
		irda_regulator-supply = <&vreg_l9b_2p5>;
		spi-max-frequency = <5000000>;
	};
};

&iris {
	firmware-name = "qcom/sm8750/realme/pista/vpu35_4v.mbn";
	status = "okay";
};

&gpu {
	status = "okay";
};

&gpu_zap_shader {
	firmware-name = "qcom/gen80000_zap.mbn";
};

&usb {
	dr_mode = "otg";
	role-switch-default-mode = "peripheral";
	maximum-speed = "high-speed";
	qcom,select-utmi-as-pipe-clk;
	phys = <&usb_hsphy>;
	phy-names = "usb2-phy";
	status = "okay";
};

&usb_dwc3_hs {
	remote-endpoint = <&pmic_glink_hs_in>;
};

/*
 * Upstream sm8750.dtsi currently defines only hot (120C) and critical (125C)
 * trips without passive cooling-maps. Add 95C passive throttling for Adreno 830
 * (gpuss0..7) and Oryon CPU clusters so sustained workloads smoothly throttle
 * instead of hitting the 125C emergency thermal shutdown.
 */
&{/thermal-zones} {
	gpuss0-thermal {
		polling-delay-passive = <10>;
		trips {
			gpuss0_alert0: gpuss0-alert0 {
				temperature = <95000>;
				hysteresis = <2000>;
				type = "passive";
			};
		};
		cooling-maps {
			map0 {
				trip = <&gpuss0_alert0>;
				cooling-device = <&gpu THERMAL_NO_LIMIT THERMAL_NO_LIMIT>;
			};
		};
	};

	gpuss1-thermal {
		polling-delay-passive = <10>;
		trips {
			gpuss1_alert0: gpuss1-alert0 {
				temperature = <95000>;
				hysteresis = <2000>;
				type = "passive";
			};
		};
		cooling-maps {
			map0 {
				trip = <&gpuss1_alert0>;
				cooling-device = <&gpu THERMAL_NO_LIMIT THERMAL_NO_LIMIT>;
			};
		};
	};

	gpuss2-thermal {
		polling-delay-passive = <10>;
		trips {
			gpuss2_alert0: gpuss2-alert0 {
				temperature = <95000>;
				hysteresis = <2000>;
				type = "passive";
			};
		};
		cooling-maps {
			map0 {
				trip = <&gpuss2_alert0>;
				cooling-device = <&gpu THERMAL_NO_LIMIT THERMAL_NO_LIMIT>;
			};
		};
	};

	gpuss3-thermal {
		polling-delay-passive = <10>;
		trips {
			gpuss3_alert0: gpuss3-alert0 {
				temperature = <95000>;
				hysteresis = <2000>;
				type = "passive";
			};
		};
		cooling-maps {
			map0 {
				trip = <&gpuss3_alert0>;
				cooling-device = <&gpu THERMAL_NO_LIMIT THERMAL_NO_LIMIT>;
			};
		};
	};

	gpuss4-thermal {
		polling-delay-passive = <10>;
		trips {
			gpuss4_alert0: gpuss4-alert0 {
				temperature = <95000>;
				hysteresis = <2000>;
				type = "passive";
			};
		};
		cooling-maps {
			map0 {
				trip = <&gpuss4_alert0>;
				cooling-device = <&gpu THERMAL_NO_LIMIT THERMAL_NO_LIMIT>;
			};
		};
	};

	gpuss5-thermal {
		polling-delay-passive = <10>;
		trips {
			gpuss5_alert0: gpuss5-alert0 {
				temperature = <95000>;
				hysteresis = <2000>;
				type = "passive";
			};
		};
		cooling-maps {
			map0 {
				trip = <&gpuss5_alert0>;
				cooling-device = <&gpu THERMAL_NO_LIMIT THERMAL_NO_LIMIT>;
			};
		};
	};

	gpuss6-thermal {
		polling-delay-passive = <10>;
		trips {
			gpuss6_alert0: gpuss6-alert0 {
				temperature = <95000>;
				hysteresis = <2000>;
				type = "passive";
			};
		};
		cooling-maps {
			map0 {
				trip = <&gpuss6_alert0>;
				cooling-device = <&gpu THERMAL_NO_LIMIT THERMAL_NO_LIMIT>;
			};
		};
	};

	gpuss7-thermal {
		polling-delay-passive = <10>;
		trips {
			gpuss7_alert0: gpuss7-alert0 {
				temperature = <95000>;
				hysteresis = <2000>;
				type = "passive";
			};
		};
		cooling-maps {
			map0 {
				trip = <&gpuss7_alert0>;
				cooling-device = <&gpu THERMAL_NO_LIMIT THERMAL_NO_LIMIT>;
			};
		};
	};

	cpu-0-0-0-thermal {
		polling-delay-passive = <100>;
		trips {
			cpu0_0_alert0: cpu-0-0-0-alert0 {
				temperature = <95000>;
				hysteresis = <2000>;
				type = "passive";
			};
		};
		cooling-maps {
			map0 {
				trip = <&cpu0_0_alert0>;
				cooling-device = <&cpu0 THERMAL_NO_LIMIT THERMAL_NO_LIMIT>;
			};
		};
	};

	cpu-0-1-0-thermal {
		polling-delay-passive = <100>;
		trips {
			cpu0_1_alert0: cpu-0-1-0-alert0 {
				temperature = <95000>;
				hysteresis = <2000>;
				type = "passive";
			};
		};
		cooling-maps {
			map0 {
				trip = <&cpu0_1_alert0>;
				cooling-device = <&cpu0 THERMAL_NO_LIMIT THERMAL_NO_LIMIT>;
			};
		};
	};

	cpu-0-2-0-thermal {
		polling-delay-passive = <100>;
		trips {
			cpu0_2_alert0: cpu-0-2-0-alert0 {
				temperature = <95000>;
				hysteresis = <2000>;
				type = "passive";
			};
		};
		cooling-maps {
			map0 {
				trip = <&cpu0_2_alert0>;
				cooling-device = <&cpu0 THERMAL_NO_LIMIT THERMAL_NO_LIMIT>;
			};
		};
	};

	cpu-0-3-0-thermal {
		polling-delay-passive = <100>;
		trips {
			cpu0_3_alert0: cpu-0-3-0-alert0 {
				temperature = <95000>;
				hysteresis = <2000>;
				type = "passive";
			};
		};
		cooling-maps {
			map0 {
				trip = <&cpu0_3_alert0>;
				cooling-device = <&cpu0 THERMAL_NO_LIMIT THERMAL_NO_LIMIT>;
			};
		};
	};

	cpu-0-4-0-thermal {
		polling-delay-passive = <100>;
		trips {
			cpu0_4_alert0: cpu-0-4-0-alert0 {
				temperature = <95000>;
				hysteresis = <2000>;
				type = "passive";
			};
		};
		cooling-maps {
			map0 {
				trip = <&cpu0_4_alert0>;
				cooling-device = <&cpu0 THERMAL_NO_LIMIT THERMAL_NO_LIMIT>;
			};
		};
	};

	cpu-0-5-0-thermal {
		polling-delay-passive = <100>;
		trips {
			cpu0_5_alert0: cpu-0-5-0-alert0 {
				temperature = <95000>;
				hysteresis = <2000>;
				type = "passive";
			};
		};
		cooling-maps {
			map0 {
				trip = <&cpu0_5_alert0>;
				cooling-device = <&cpu0 THERMAL_NO_LIMIT THERMAL_NO_LIMIT>;
			};
		};
	};

	cpu-1-0-0-thermal {
		polling-delay-passive = <100>;
		trips {
			cpu1_0_alert0: cpu-1-0-0-alert0 {
				temperature = <95000>;
				hysteresis = <2000>;
				type = "passive";
			};
		};
		cooling-maps {
			map0 {
				trip = <&cpu1_0_alert0>;
				cooling-device = <&cpu6 THERMAL_NO_LIMIT THERMAL_NO_LIMIT>;
			};
		};
	};

	cpu-1-1-0-thermal {
		polling-delay-passive = <100>;
		trips {
			cpu1_1_alert0: cpu-1-1-0-alert0 {
				temperature = <95000>;
				hysteresis = <2000>;
				type = "passive";
			};
		};
		cooling-maps {
			map0 {
				trip = <&cpu1_1_alert0>;
				cooling-device = <&cpu6 THERMAL_NO_LIMIT THERMAL_NO_LIMIT>;
			};
		};
	};
};
